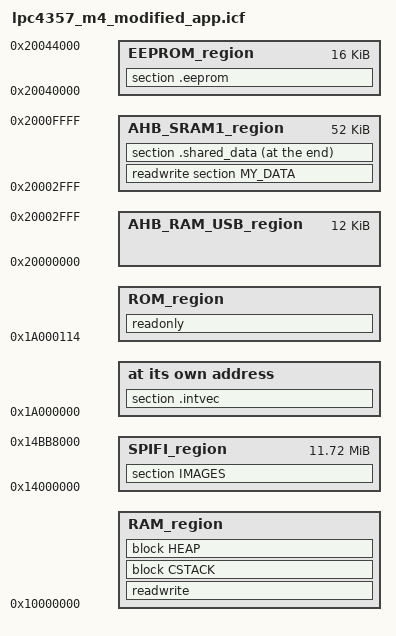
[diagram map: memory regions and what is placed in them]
/*###ICF### Section handled by ICF editor, don't touch! ****/
/*-Editor annotation file-*/
/* IcfEditorFile="$TOOLKIT_DIR$\config\ide\IcfEditor\cortex_v1_0.xml" */
/*-Specials-*/
define symbol __ICFEDIT_intvec_start__ = 0x1A000000;
/*-Memory Regions-*/
define symbol __ICFEDIT_region_ROM_start__ = 0x1A000114;
define symbol __ICFEDIT_region_ROM_end__   = 0x1A07FFFF;
define symbol __ICFEDIT_region_RAM_start__ = 0x10000000;
define symbol __ICFEDIT_region_RAM_end__   = 0x10008000;
/*-Sizes-*/
define symbol __ICFEDIT_size_cstack__ = 0x2000;
define symbol __ICFEDIT_size_heap__   = 0x2000;
/**** End of ICF editor section. ###ICF###*/

/********** Flash BankB Region **********/
define symbol __ICFEDIT_region_ROM_BANKB_start__ = 0x1B000000;
define symbol __ICFEDIT_region_ROM_BANKB_end__   = 0x1B07FFFF;

/********** Local SRAM Region **********/
define symbol LOCAL_SRAM_start__    = 0x10080000;
define symbol LOCAL_SRAM_end__      = 0x10089FFF;

/********** AHB SRAM Region 1 **********/
define symbol AHB_SRAM1_start__     = 0x20000000;
define symbol AHB_SRAM1_end__       = 0x2000FFFF;

/* bank 3 RAM - 3K reserved for USB */
define symbol _AHB_RAM_USB_start__  = 0x20000000;
define symbol _AHB_RAM_USB_end__    = 0x20002FFF;

/********* CRP REGION *********/
define symbol __CRP_start__   = 0x1A0002FC;
define symbol __CRP_end__     = 0x1A0002FF;

/********* EEPROM REGION *********/
define symbol __EE_start__   = 0x20040000;
define symbol __EE_end__     = 0x20044000;

/********* SPIFI REGION *********/
define symbol __SPIFI_start__ = 0x14000000;
define symbol __SPIFI_end__ = 0x14BB8000;

define memory mem with size = 4G;
define region ROM_region           = mem:[from __ICFEDIT_region_ROM_start__   to __ICFEDIT_region_ROM_BANKB_end__] - mem:[from  __ICFEDIT_region_ROM_end__ to __ICFEDIT_region_ROM_BANKB_start__];
define region RAM_region           = mem:[from __ICFEDIT_region_RAM_start__   to LOCAL_SRAM_end__] - mem:[from  __ICFEDIT_region_RAM_end__ to LOCAL_SRAM_start__];
/*define region LOCAL_SRAM_region    = mem:[from LOCAL_SRAM_start__             to LOCAL_SRAM_end__];*/
define region AHB_SRAM1_region     = mem:[from _AHB_RAM_USB_end__             to AHB_SRAM1_end__];
define region EEPROM_region        = mem:[from  __EE_start__ to __EE_end__];
define region AHB_RAM_USB_region   = mem:[from _AHB_RAM_USB_start__ to _AHB_RAM_USB_end__];
define region SPIFI_region         = mem:[from __SPIFI_start__ to __SPIFI_end__];


define block CSTACK    with alignment = 8, size = __ICFEDIT_size_cstack__   { };
define block HEAP      with alignment = 8, size = __ICFEDIT_size_heap__     { };

initialize by copy { readwrite };
do not initialize  { section .noinit };
do not initialize  { section .eeprom };
initialize by copy { section IMAGES};

place at address mem:__ICFEDIT_intvec_start__ { section .intvec };

place in AHB_SRAM1_region        { readwrite section MY_DATA };
place at end of AHB_SRAM1_region { section .shared_data};
/*place in AHB_SRAM1_region      { section .ahb_sram1 };*/
place in EEPROM_region           { section .eeprom };
place in SPIFI_region            { section IMAGES};


place in ROM_region              { readonly };
place in RAM_region              { readwrite,
                                   block CSTACK, block HEAP };
